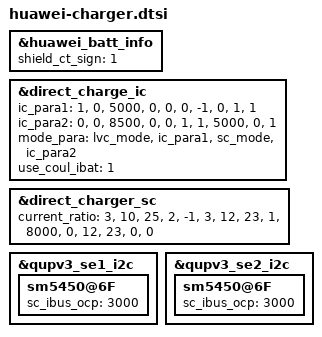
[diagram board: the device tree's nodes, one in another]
&huawei_batt_info {
    shield_ct_sign = <1>;
};

&direct_charge_ic {
	/* ic_index  path_index  max_ibat  ibat_sample_point  vbat_sample_point */
	ic_para1 =
		"1", "0", "5000", "0", "0",
		"0", "-1", "0", "1", "1";
	ic_para2 =
		"0", "0", "8500", "0", "0",
		"1", "1", "5000", "0", "1";
	mode_para =
		"lvc_mode", "ic_para1",
		"sc_mode", "ic_para2";
        use_coul_ibat = <1>;
	status = "ok";
};

&direct_charger_sc {
	current_ratio =
		"3", "10", "25", "2", "-1",
		"3", "12", "23", "1", "8000",
		"0", "12", "23", "0", "0";
};

&qupv3_se1_i2c {
	sm5450@6F {
		sc_ibus_ocp = <3000>;
	};
};

&qupv3_se2_i2c {
	sm5450@6F {
		sc_ibus_ocp = <3000>;
	};
};
